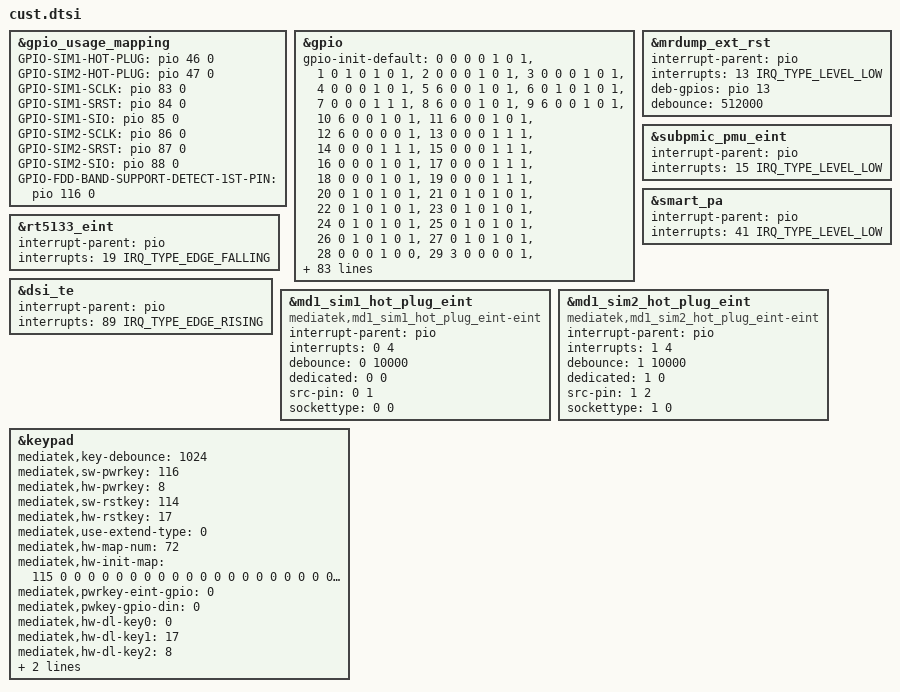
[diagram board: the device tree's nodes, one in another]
/*
 * Generated by MTK SP DrvGen Version: 3.5.160809 for MT6878.
 * 2026-10-19 13:55:33
 * Do Not Modify The File.
 * Copyright Mediatek Inc. (c) 2016.
*/

/*************************
 * ADC DTSI File
*************************/



/*************************
 * CLK_BUF DTSI File
*************************/



/*************************
 * I2C DTSI File
*************************/



/*************************
 * GPIO DTSI File
*************************/

&gpio_usage_mapping {
	GPIO-SIM1-HOT-PLUG = <&pio 46 0>;
	GPIO-SIM2-HOT-PLUG = <&pio 47 0>;
	GPIO-SIM1-SCLK = <&pio 83 0>;
	GPIO-SIM1-SRST = <&pio 84 0>;
	GPIO-SIM1-SIO = <&pio 85 0>;
	GPIO-SIM2-SCLK = <&pio 86 0>;
	GPIO-SIM2-SRST = <&pio 87 0>;
	GPIO-SIM2-SIO = <&pio 88 0>;
	GPIO-FDD-BAND-SUPPORT-DETECT-1ST-PIN = <&pio 116 0>;
};

&gpio{
	gpio-init-default = <0 0 0 0 1 0 1>,
		<1 0 1 0 1 0 1>,
		<2 0 0 0 1 0 1>,
		<3 0 0 0 1 0 1>,
		<4 0 0 0 1 0 1>,
		<5 6 0 0 1 0 1>,
		<6 0 1 0 1 0 1>,
		<7 0 0 0 1 1 1>,
		<8 6 0 0 1 0 1>,
		<9 6 0 0 1 0 1>,
		<10 6 0 0 1 0 1>,
		<11 6 0 0 1 0 1>,
		<12 6 0 0 0 0 1>,
		<13 0 0 0 1 1 1>,
		<14 0 0 0 1 1 1>,
		<15 0 0 0 1 1 1>,
		<16 0 0 0 1 0 1>,
		<17 0 0 0 1 1 1>,
		<18 0 0 0 1 0 1>,
		<19 0 0 0 1 1 1>,
		<20 0 1 0 1 0 1>,
		<21 0 1 0 1 0 1>,
		<22 0 1 0 1 0 1>,
		<23 0 1 0 1 0 1>,
		<24 0 1 0 1 0 1>,
		<25 0 1 0 1 0 1>,
		<26 0 1 0 1 0 1>,
		<27 0 1 0 1 0 1>,
		<28 0 0 0 1 0 0>,
		<29 3 0 0 0 0 1>,
		<30 3 0 0 1 1 1>,
		<31 3 0 0 0 0 1>,
		<32 3 0 0 1 1 1>,
		<33 0 0 0 1 0 0>,
		<34 0 0 0 1 0 0>,
		<35 0 0 0 1 0 0>,
		<36 1 0 0 1 0 1>,
		<37 0 0 0 1 0 0>,
		<38 0 0 0 1 0 0>,
		<39 0 0 0 1 0 0>,
		<40 0 1 0 1 0 1>,
		<41 0 0 0 1 0 1>,
		<42 2 0 0 0 0 1>,
		<43 2 0 0 0 0 1>,
		<44 2 0 0 1 0 1>,
		<45 2 0 0 0 0 1>,
		<46 1 0 0 1 1 1>,
		<47 1 0 0 1 1 1>,
		<48 1 0 0 0 0 1>,
		<49 1 0 0 1 1 1>,
		<50 7 0 0 0 0 1>,
		<51 7 0 0 1 1 1>,
		<52 1 0 0 1 0 1>,
		<53 0 0 0 1 0 0>,
		<54 1 0 0 1 1 1>,
		<55 7 0 0 1 0 1>,
		<56 7 0 0 1 0 1>,
		<57 7 0 0 1 0 1>,
		<58 7 0 0 0 0 1>,
		<59 7 0 0 1 0 1>,
		<60 1 0 0 1 0 1>,
		<61 1 0 0 1 1 1>,
		<62 1 0 0 1 0 1>,
		<63 1 0 0 1 0 1>,
		<64 1 0 0 1 0 1>,
		<65 1 0 0 1 1 1>,
		<66 1 0 0 1 0 1>,
		<67 1 0 0 1 0 1>,
		<68 2 0 0 1 0 1>,
		<69 2 0 0 1 1 1>,
		<70 2 0 0 1 0 1>,
		<71 2 0 0 1 0 1>,
		<72 2 0 0 1 0 1>,
		<73 2 0 0 1 1 1>,
		<74 2 0 0 1 0 1>,
		<75 2 0 0 1 0 1>,
		<77 1 0 0 0 0 1>,
		<78 1 0 0 1 1 1>,
		<79 1 0 0 1 1 1>,
		<80 1 0 0 1 1 1>,
		<81 1 0 0 1 1 1>,
		<82 1 0 0 1 1 1>,
		<83 1 0 0 0 0 1>,
		<84 1 0 0 0 0 1>,
		<85 1 0 0 1 1 1>,
		<86 1 0 0 0 0 1>,
		<87 1 0 0 0 0 1>,
		<88 1 0 0 1 1 1>,
		<89 1 0 0 1 0 1>,
		<90 1 0 0 1 0 1>,
		<91 1 0 0 1 0 1>,
		<92 0 0 0 1 0 1>,
		<93 1 0 0 1 0 1>,
		<94 1 0 0 1 0 1>,
		<95 1 0 0 1 0 1>,
		<96 1 0 0 1 0 1>,
		<97 1 0 0 1 0 1>,
		<98 1 0 0 1 0 1>,
		<99 1 0 0 0 0 1>,
		<100 1 0 0 0 0 1>,
		<101 1 0 0 0 0 1>,
		<102 1 0 0 0 0 1>,
		<103 1 0 0 0 0 1>,
		<104 1 0 0 0 0 1>,
		<105 1 0 0 0 0 1>,
		<106 1 0 0 0 0 1>,
		<107 1 0 0 0 0 1>,
		<108 1 0 0 0 0 1>,
		<109 1 0 0 0 0 1>,
		<110 1 0 0 0 0 1>,
		<111 1 0 0 0 0 1>,
		<112 1 0 0 0 0 1>,
		<113 1 0 0 0 0 1>,
		<114 1 0 0 0 0 1>,
		<115 0 0 0 1 0 1>,
		<116 0 0 0 1 0 1>,
		<117 1 0 0 0 0 0>,
		<118 1 0 0 1 0 0>,
		<119 1 0 0 0 0 0>,
		<120 1 0 0 1 0 0>,
		<121 1 0 0 0 0 0>,
		<122 1 0 0 1 0 0>,
		<123 1 0 0 1 0 1>,
		<124 1 0 0 1 0 1>,
		<125 2 0 0 1 1 1>,
		<126 2 0 0 1 1 1>,
		<127 2 0 0 1 1 1>,
		<128 2 0 0 1 1 1>,
		<129 1 0 0 1 1 1>,
		<130 1 0 0 1 1 1>,
		<131 0 0 0 1 0 1>,
		<132 0 0 0 1 0 1>,
		<133 1 0 0 1 1 1>,
		<134 1 0 0 1 1 1>,
		<135 1 0 0 1 1 1>,
		<136 1 0 0 1 1 1>,
		<137 1 0 0 1 1 1>,
		<138 1 0 0 1 1 1>,
		<139 1 0 0 1 1 1>,
		<140 1 0 0 1 1 1>,
		<141 1 0 0 1 1 1>,
		<142 1 0 0 1 1 1>,
		<143 2 1 0 1 0 1>,
		<144 2 1 0 1 0 1>,
		<145 2 0 0 1 1 1>,
		<146 2 0 0 1 1 1>,
		<147 2 0 0 1 1 1>,
		<148 2 0 0 1 1 1>,
		<149 0 1 0 1 0 1>,
		<150 0 1 0 1 0 1>,
		<151 0 1 0 1 0 1>,
		<152 0 0 0 1 0 1>,
		<153 0 1 0 1 0 1>,
		<154 0 1 0 1 0 1>,
		<155 0 1 0 1 0 1>,
		<156 1 0 0 0 0 1>,
		<157 1 0 0 0 0 1>,
		<158 1 0 0 0 0 1>,
		<159 1 0 0 0 0 1>,
		<160 1 0 0 0 0 1>,
		<161 1 0 0 0 0 1>,
		<162 1 0 0 1 0 1>,
		<163 1 0 0 0 0 1>,
		<164 1 0 0 0 0 1>,
		<165 1 0 0 1 0 1>,
		<166 1 0 0 0 0 1>,
		<167 1 0 0 0 0 1>,
		<168 1 0 0 0 0 1>,
		<169 1 0 0 0 0 1>,
		<170 1 0 0 1 0 1>,
		<171 1 0 0 1 0 1>,
		<172 0 0 0 1 0 1>,
		<173 0 0 0 1 0 1>,
		<174 0 0 0 1 0 1>,
		<175 0 0 0 1 0 1>,
		<176 0 0 0 1 0 1>,
		<177 0 0 0 1 0 1>,
		<178 0 0 0 1 0 1>,
		<179 0 0 0 1 0 1>,
		<180 0 0 0 1 0 1>,
		<181 0 0 0 1 0 1>,
		<182 0 0 0 1 0 1>,
		<183 1 0 0 1 0 1>,
		<184 0 0 0 1 0 0>,
		<185 0 0 0 1 0 0>,
		<186 0 0 0 1 0 0>,
		<187 0 0 0 1 0 0>,
		<188 0 0 0 1 0 0>,
		<189 0 0 0 1 0 0>,
		<190 0 0 0 1 0 0>,
		<191 0 0 0 1 0 0>,
		<192 0 0 0 1 0 0>,
		<193 0 0 0 1 0 0>,
		<194 0 0 0 1 0 0>,
		<195 0 0 0 1 0 0>;
};


/*************************
 * EINT DTSI File
*************************/

#include <dt-bindings/interrupt-controller/irq.h>
#include <dt-bindings/interrupt-controller/arm-gic.h>

&mrdump_ext_rst {
	interrupt-parent = <&pio>;
	interrupts = <13 IRQ_TYPE_LEVEL_LOW>;
	deb-gpios = <&pio 13 0>;
	debounce = <512000>;
	status = "okay";
};

&subpmic_pmu_eint {
	interrupt-parent = <&pio>;
	interrupts = <15 IRQ_TYPE_LEVEL_LOW>;
	status = "okay";
};

&rt5133_eint {
	interrupt-parent = <&pio>;
	interrupts = <19 IRQ_TYPE_EDGE_FALLING>;
	status = "okay";
};

&smart_pa {
	interrupt-parent = <&pio>;
	interrupts = <41 IRQ_TYPE_LEVEL_LOW>;
	status = "okay";
};

&dsi_te {
	interrupt-parent = <&pio>;
	interrupts = <89 IRQ_TYPE_EDGE_RISING>;
	status = "okay";
};



/*************************
 * MD1_EINT DTSI File
*************************/

&md1_sim1_hot_plug_eint {
	compatible = "mediatek,md1_sim1_hot_plug_eint-eint";
	interrupt-parent = <&pio>;
	interrupts = <0 4>;
	debounce = <0 10000>;
	dedicated = <0 0>;
	src-pin = <0 1>;
	sockettype = <0 0>;
	status = "okay";
};

&md1_sim2_hot_plug_eint {
	compatible = "mediatek,md1_sim2_hot_plug_eint-eint";
	interrupt-parent = <&pio>;
	interrupts = <1 4>;
	debounce = <1 10000>;
	dedicated = <1 0>;
	src-pin = <1 2>;
	sockettype = <1 0>;
	status = "okay";
};



/*************************
 * PMIC DTSI File
*************************/



/*************************
 * POWER DTSI File
*************************/



/*************************
 * KPD DTSI File
*************************/

&keypad {
	mediatek,key-debounce = <1024>;
	mediatek,sw-pwrkey = <116>;
	mediatek,hw-pwrkey = <8>;
	mediatek,sw-rstkey  = <114>;
	mediatek,hw-rstkey = <17>;
	mediatek,use-extend-type = <0>;
	/*HW Keycode [0~71] -> Linux Keycode*/
	mediatek,hw-map-num = <72>;
	mediatek,hw-init-map = <115 0 0 0 0 0 0 0 0 0 0 0 0 0 0 0 0 0 0 0 0 0 0 0 0 0 0 0 0 0 0 0 0 0 0 0 0 0 0 0 0 0 0 0 0 0 0 0 0 0 0 0 0 0 0 0 0 0 0 0 0 0 0 0 0 0 0 0 0 0 0 0 >;
	mediatek,pwrkey-eint-gpio = <0>;
	mediatek,pwkey-gpio-din  = <0>;
	mediatek,hw-dl-key0 = <0>;
	mediatek,hw-dl-key1 = <17>;
	mediatek,hw-dl-key2 = <8>;
	mediatek,hw-recovery-key = <0>;
	mediatek,hw-factory-key = <17>;
	status = "okay";
};


